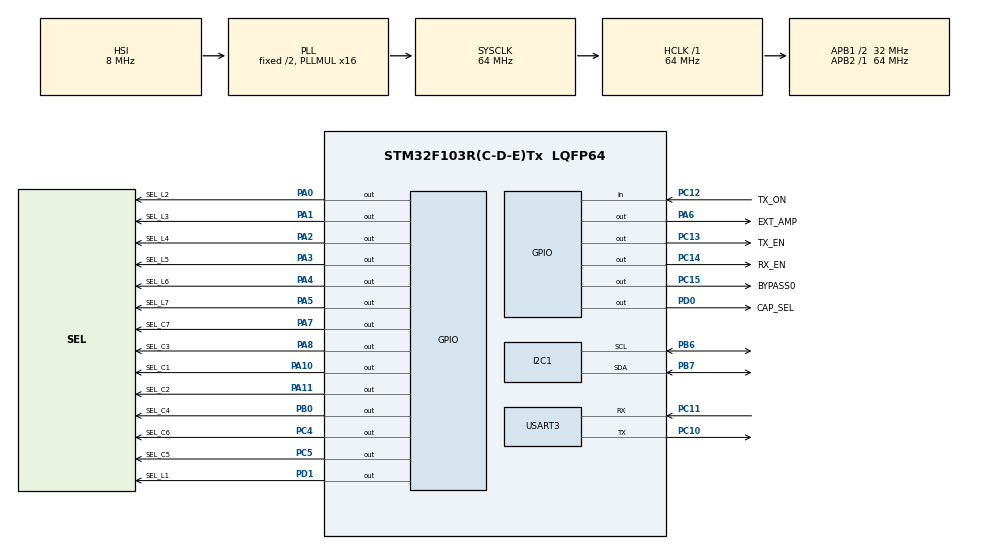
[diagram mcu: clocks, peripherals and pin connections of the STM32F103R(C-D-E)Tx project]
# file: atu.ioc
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Dma.Request0=USART3_RX
Dma.USART3_RX.0.Direction=DMA_PERIPH_TO_MEMORY
Dma.USART3_RX.0.Instance=DMA1_Channel3
Dma.USART3_RX.0.MemDataAlignment=DMA_MDATAALIGN_BYTE
Dma.USART3_RX.0.MemInc=DMA_MINC_ENABLE
Dma.USART3_RX.0.Mode=DMA_CIRCULAR
Dma.USART3_RX.0.PeriphDataAlignment=DMA_PDATAALIGN_BYTE
Dma.USART3_RX.0.PeriphInc=DMA_PINC_DISABLE
Dma.USART3_RX.0.Priority=DMA_PRIORITY_LOW
Mcu.Family=STM32F1
Mcu.Name=STM32F103R(C-D-E)Tx
Mcu.Package=LQFP64
NVIC.DMA1_Channel3_IRQn=true\:8\:0\:true\:false\:true\:false\:true\:true
NVIC.I2C1_ER_IRQn=true\:10\:0\:true\:false\:true\:true\:true\:true
NVIC.I2C1_EV_IRQn=true\:10\:0\:true\:false\:true\:true\:true\:true
NVIC.PriorityGroup=NVIC_PRIORITYGROUP_4
PA0-WKUP.GPIO_Label=SEL_L2
PA0-WKUP.Signal=GPIO_Output
PA1.GPIO_Label=SEL_L3
PA1.Signal=GPIO_Output
PA10.GPIO_Label=SEL_C1
PA10.Signal=GPIO_Output
PA11.GPIO_Label=SEL_C2
PA11.Signal=GPIO_Output
PA13.Mode=Trace_Asynchronous_SW
PA13.Signal=SYS_JTMS-SWDIO
PA14.Mode=Trace_Asynchronous_SW
PA14.Signal=SYS_JTCK-SWCLK
PA2.GPIO_Label=SEL_L4
PA2.Signal=GPIO_Output
PA3.GPIO_Label=SEL_L5
PA3.Signal=GPIO_Output
PA4.GPIO_Label=SEL_L6
PA4.Signal=GPIO_Output
PA5.GPIO_Label=SEL_L7
PA5.Signal=GPIO_Output
PA6.GPIO_Label=EXT_AMP
PA6.Signal=GPIO_Output
PA7.GPIO_Label=SEL_C7
PA7.Signal=GPIO_Output
PA8.GPIO_Label=SEL_C3
PA8.Signal=GPIO_Output
PB0.GPIO_Label=SEL_C4
PB0.Signal=GPIO_Output
PB3.Mode=Trace_Asynchronous_SW
PB3.Signal=SYS_JTDO-TRACESWO
PB6.Mode=I2C
PB6.Signal=I2C1_SCL
PB7.Mode=I2C
PB7.Signal=I2C1_SDA
PC10.Mode=Asynchronous
PC10.Signal=USART3_TX
PC11.Mode=Asynchronous
PC11.Signal=USART3_RX
PC12.GPIO_Label=TX_ON
PC12.GPIO_PuPd=GPIO_PULLDOWN
PC12.Signal=GPIO_Input
PC13-TAMPER-RTC.GPIO_Label=TX_EN
PC13-TAMPER-RTC.Signal=GPIO_Output
PC14-OSC32_IN.GPIO_Label=RX_EN
PC14-OSC32_IN.Signal=GPIO_Output
PC15-OSC32_OUT.GPIO_Label=BYPASS0
PC15-OSC32_OUT.Signal=GPIO_Output
PC4.GPIO_Label=SEL_C6
PC4.Signal=GPIO_Output
PC5.GPIO_Label=SEL_C5
PC5.Signal=GPIO_Output
PD0-OSC_IN.GPIO_Label=CAP_SEL
PD0-OSC_IN.Signal=GPIO_Output
PD1-OSC_OUT.GPIO_Label=SEL_L1
PD1-OSC_OUT.Signal=GPIO_Output
ProjectManager.HeapSize=0x200
ProjectManager.StackSize=0x400
ProjectManager.TargetToolchain=STM32CubeIDE
RCC.AHBFreq_Value=64000000
RCC.APB1CLKDivider=RCC_HCLK_DIV2
RCC.APB1Freq_Value=32000000
RCC.APB1TimFreq_Value=64000000
RCC.APB2Freq_Value=64000000
RCC.APB2TimFreq_Value=64000000
RCC.HCLKFreq_Value=64000000
RCC.PLLMUL=RCC_PLL_MUL16
RCC.SYSCLKFreq_VALUE=64000000
RCC.SYSCLKSource=RCC_SYSCLKSOURCE_PLLCLK
RCC.USBFreq_Value=64000000
USART3.VirtualMode=VM_ASYNC
board=custom

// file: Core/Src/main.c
/* USER CODE BEGIN Header */
/**
  ******************************************************************************
  * @file           : main.c
  * @brief          : Main program body
  ******************************************************************************
  * @attention
  *
  * Copyright (c) 2025 STMicroelectronics.
  * All rights reserved.
  *
  * This software is licensed under terms that can be found in the LICENSE file
  * in the root directory of this software component.
  * If no LICENSE file comes with this software, it is provided AS-IS.
  *
  ******************************************************************************
  */
/* USER CODE END Header */
#include "main.h"

/* USER CODE BEGIN Includes */
#include "cmd.h"
#include "gpio.h"
/* USER CODE END Includes */

I2C_HandleTypeDef hi2c1;

UART_HandleTypeDef huart3;
DMA_HandleTypeDef hdma_usart3_rx;

void SystemClock_Config(void);
static void MX_GPIO_Init(void);
static void MX_DMA_Init(void);
static void MX_I2C1_Init(void);
static void MX_USART3_UART_Init(void);

int main(void)
{

  /* MCU Configuration--------------------------------------------------------*/

  /* Reset of all peripherals, Initializes the Flash interface and the Systick. */
  HAL_Init();

  /* Configure the system clock */
  SystemClock_Config();

  /* Initialize all configured peripherals */
  MX_GPIO_Init();
  MX_DMA_Init();
  MX_I2C1_Init();
  MX_USART3_UART_Init();
  /* USER CODE BEGIN 2 */
  gpio_tx_off();
  cmd_start();
  /* USER CODE END 2 */

  /* Infinite loop */
  while (1)
  {

    /* USER CODE BEGIN 3 */
	  cmd_tick();
	  gpio_tick();
  }
  /* USER CODE END 3 */
}

void SystemClock_Config(void)
{
  RCC_OscInitTypeDef RCC_OscInitStruct = {0};
  RCC_ClkInitTypeDef RCC_ClkInitStruct = {0};

  /** Initializes the RCC Oscillators according to the specified parameters
  * in the RCC_OscInitTypeDef structure.
  */
  RCC_OscInitStruct.OscillatorType = RCC_OSCILLATORTYPE_HSI;
  RCC_OscInitStruct.HSIState = RCC_HSI_ON;
  RCC_OscInitStruct.HSICalibrationValue = RCC_HSICALIBRATION_DEFAULT;
  RCC_OscInitStruct.PLL.PLLState = RCC_PLL_ON;
  RCC_OscInitStruct.PLL.PLLSource = RCC_PLLSOURCE_HSI_DIV2;
  RCC_OscInitStruct.PLL.PLLMUL = RCC_PLL_MUL16;
  if (HAL_RCC_OscConfig(&RCC_OscInitStruct) != HAL_OK)
  {
    Error_Handler();
  }

  /** Initializes the CPU, AHB and APB buses clocks
  */
  RCC_ClkInitStruct.ClockType = RCC_CLOCKTYPE_HCLK|RCC_CLOCKTYPE_SYSCLK
                              |RCC_CLOCKTYPE_PCLK1|RCC_CLOCKTYPE_PCLK2;
  RCC_ClkInitStruct.SYSCLKSource = RCC_SYSCLKSOURCE_PLLCLK;
  RCC_ClkInitStruct.AHBCLKDivider = RCC_SYSCLK_DIV1;
  RCC_ClkInitStruct.APB1CLKDivider = RCC_HCLK_DIV2;
  RCC_ClkInitStruct.APB2CLKDivider = RCC_HCLK_DIV1;

  if (HAL_RCC_ClockConfig(&RCC_ClkInitStruct, FLASH_LATENCY_2) != HAL_OK)
  {
    Error_Handler();
  }
}

static void MX_I2C1_Init(void)
{

  hi2c1.Instance = I2C1;
  hi2c1.Init.ClockSpeed = 100000;
  hi2c1.Init.DutyCycle = I2C_DUTYCYCLE_2;
  hi2c1.Init.OwnAddress1 = 0;
  hi2c1.Init.AddressingMode = I2C_ADDRESSINGMODE_7BIT;
  hi2c1.Init.DualAddressMode = I2C_DUALADDRESS_DISABLE;
  hi2c1.Init.OwnAddress2 = 0;
  hi2c1.Init.GeneralCallMode = I2C_GENERALCALL_DISABLE;
  hi2c1.Init.NoStretchMode = I2C_NOSTRETCH_DISABLE;
  if (HAL_I2C_Init(&hi2c1) != HAL_OK)
  {
    Error_Handler();
  }

}

static void MX_USART3_UART_Init(void)
{

  huart3.Instance = USART3;
  huart3.Init.BaudRate = 115200;
  huart3.Init.WordLength = UART_WORDLENGTH_8B;
  huart3.Init.StopBits = UART_STOPBITS_1;
  huart3.Init.Parity = UART_PARITY_NONE;
  huart3.Init.Mode = UART_MODE_TX_RX;
  huart3.Init.HwFlowCtl = UART_HWCONTROL_NONE;
  huart3.Init.OverSampling = UART_OVERSAMPLING_16;
  if (HAL_UART_Init(&huart3) != HAL_OK)
  {
    Error_Handler();
  }

}

static void MX_DMA_Init(void)
{

  /* DMA controller clock enable */
  __HAL_RCC_DMA1_CLK_ENABLE();

  /* DMA interrupt init */
  /* DMA1_Channel3_IRQn interrupt configuration */
  HAL_NVIC_SetPriority(DMA1_Channel3_IRQn, 8, 0);
  HAL_NVIC_EnableIRQ(DMA1_Channel3_IRQn);

}

static void MX_GPIO_Init(void)
{
  GPIO_InitTypeDef GPIO_InitStruct = {0};

  /* GPIO Ports Clock Enable */
  __HAL_RCC_GPIOC_CLK_ENABLE();
  __HAL_RCC_GPIOD_CLK_ENABLE();
  __HAL_RCC_GPIOA_CLK_ENABLE();
  __HAL_RCC_GPIOB_CLK_ENABLE();

  /*Configure GPIO pin Output Level */
  HAL_GPIO_WritePin(GPIOC, TX_EN_Pin|RX_EN_Pin|BYPASS0_Pin|SEL_C6_Pin
                          |SEL_C5_Pin, GPIO_PIN_RESET);

  /*Configure GPIO pin Output Level */
  HAL_GPIO_WritePin(GPIOD, CAP_SEL_Pin|SEL_L1_Pin, GPIO_PIN_RESET);

  /*Configure GPIO pin Output Level */
  HAL_GPIO_WritePin(GPIOA, SEL_L2_Pin|SEL_L3_Pin|SEL_L4_Pin|SEL_L5_Pin
                          |SEL_L6_Pin|SEL_L7_Pin|EXT_AMP_Pin|SEL_C7_Pin
                          |SEL_C3_Pin|SEL_C1_Pin|SEL_C2_Pin, GPIO_PIN_RESET);

  /*Configure GPIO pin Output Level */
  HAL_GPIO_WritePin(SEL_C4_GPIO_Port, SEL_C4_Pin, GPIO_PIN_RESET);

  /*Configure GPIO pins : TX_EN_Pin RX_EN_Pin BYPASS0_Pin SEL_C6_Pin
                           SEL_C5_Pin */
  GPIO_InitStruct.Pin = TX_EN_Pin|RX_EN_Pin|BYPASS0_Pin|SEL_C6_Pin
                          |SEL_C5_Pin;
  GPIO_InitStruct.Mode = GPIO_MODE_OUTPUT_PP;
  GPIO_InitStruct.Pull = GPIO_NOPULL;
  GPIO_InitStruct.Speed = GPIO_SPEED_FREQ_LOW;
  HAL_GPIO_Init(GPIOC, &GPIO_InitStruct);

  /*Configure GPIO pins : CAP_SEL_Pin SEL_L1_Pin */
  GPIO_InitStruct.Pin = CAP_SEL_Pin|SEL_L1_Pin;
  GPIO_InitStruct.Mode = GPIO_MODE_OUTPUT_PP;
  GPIO_InitStruct.Pull = GPIO_NOPULL;
  GPIO_InitStruct.Speed = GPIO_SPEED_FREQ_LOW;
  HAL_GPIO_Init(GPIOD, &GPIO_InitStruct);

  /*Configure GPIO pins : SEL_L2_Pin SEL_L3_Pin SEL_L4_Pin SEL_L5_Pin
                           SEL_L6_Pin SEL_L7_Pin EXT_AMP_Pin SEL_C7_Pin
                           SEL_C3_Pin SEL_C1_Pin SEL_C2_Pin */
  GPIO_InitStruct.Pin = SEL_L2_Pin|SEL_L3_Pin|SEL_L4_Pin|SEL_L5_Pin
                          |SEL_L6_Pin|SEL_L7_Pin|EXT_AMP_Pin|SEL_C7_Pin
                          |SEL_C3_Pin|SEL_C1_Pin|SEL_C2_Pin;
  GPIO_InitStruct.Mode = GPIO_MODE_OUTPUT_PP;
  GPIO_InitStruct.Pull = GPIO_NOPULL;
  GPIO_InitStruct.Speed = GPIO_SPEED_FREQ_LOW;
  HAL_GPIO_Init(GPIOA, &GPIO_InitStruct);

  /*Configure GPIO pin : SEL_C4_Pin */
  GPIO_InitStruct.Pin = SEL_C4_Pin;
  GPIO_InitStruct.Mode = GPIO_MODE_OUTPUT_PP;
  GPIO_InitStruct.Pull = GPIO_NOPULL;
  GPIO_InitStruct.Speed = GPIO_SPEED_FREQ_LOW;
  HAL_GPIO_Init(SEL_C4_GPIO_Port, &GPIO_InitStruct);

  /*Configure GPIO pin : TX_ON_Pin */
  GPIO_InitStruct.Pin = TX_ON_Pin;
  GPIO_InitStruct.Mode = GPIO_MODE_INPUT;
  GPIO_InitStruct.Pull = GPIO_PULLDOWN;
  HAL_GPIO_Init(TX_ON_GPIO_Port, &GPIO_InitStruct);

  /*Configure peripheral I/O remapping */
  __HAL_AFIO_REMAP_PD01_ENABLE();

}

void Error_Handler(void)
{
  __disable_irq();
  while (1)
  {
  }
}
